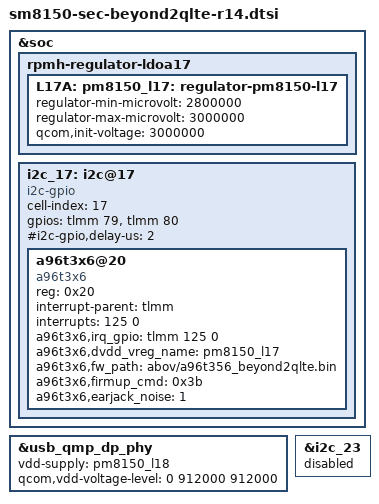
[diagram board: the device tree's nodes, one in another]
/* Copyright (c) 2016-2017, The Linux Foundation. All rights reserved.
 *
 * This program is free software; you can redistribute it and/or modify
 * it under the terms of the GNU General Public License version 2 and
 * only version 2 as published by the Free Software Foundation.
 *
 * This program is distributed in the hope that it will be useful,
 * but WITHOUT ANY WARRANTY; without even the implied warranty of
 * MERCHANTABILITY or FITNESS FOR A PARTICULAR PURPOSE.  See the
 * GNU General Public License for more details.
 */

#include "sm8150-sec-beyond2qlte-common.dtsi"
#include "sm8150-sec-beyond2qlte-optics-r12.dtsi"
#include "../../../../../drivers/motor/tuning/beyond2qlte_motor_tuning.dtsi"


&soc {
	rpmh-regulator-ldoa17 {
		L17A: pm8150_l17: regulator-pm8150-l17 {
			regulator-min-microvolt = <2800000>;
			regulator-max-microvolt = <3000000>;
			qcom,init-voltage = <3000000>;
		};
	};

	i2c_17: i2c@17 { /* SW I2C */
		status = "ok";

		cell-index = <17>;
		compatible = "i2c-gpio";
		gpios = <&tlmm 79 0 /* sda */
			 &tlmm 80 0 /* scl */
		>;
		#i2c-gpio,delay-us = <2>;
		#address-cells = <1>;
		#size-cells = <0>;
		a96t3x6@20 {
			compatible = "a96t3x6";
			reg = <0x20>;

			interrupt-parent = <&tlmm>;
			interrupts = <125 0>;

			a96t3x6,irq_gpio = <&tlmm 125 0>;
			a96t3x6,dvdd_vreg_name = "pm8150_l17";
			a96t3x6,fw_path = "abov/a96t356_beyond2qlte.bin";
			a96t3x6,firmup_cmd = <0x3b>;
			a96t3x6,earjack_noise = <1>;
		};
	};	
};

&usb_qmp_dp_phy {
	vdd-supply = <&pm8150_l18>;
	qcom,vdd-voltage-level = <0 912000 912000>;
};

&i2c_23 {
	status = "disabled";
};

